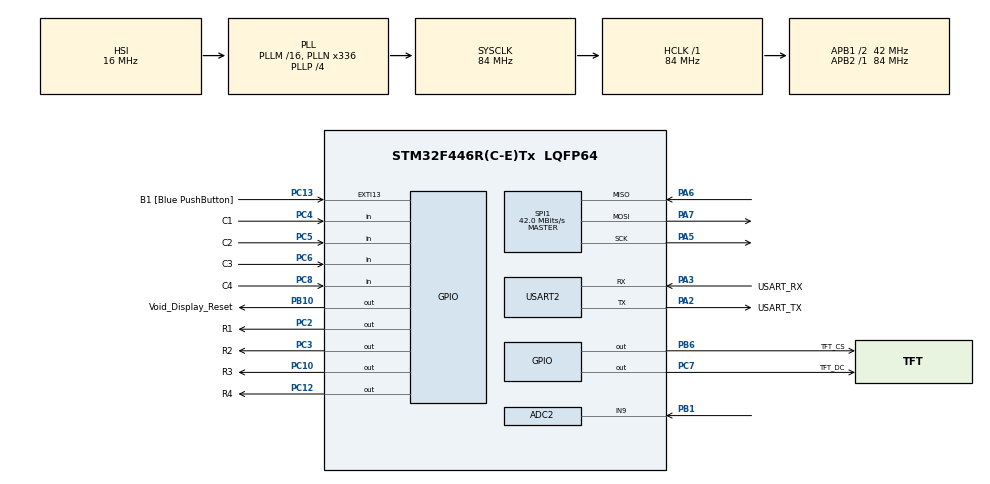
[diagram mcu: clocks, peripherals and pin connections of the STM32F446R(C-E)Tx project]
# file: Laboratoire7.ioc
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ADC1.Channel-0\#ChannelRegularConversion=ADC_CHANNEL_TEMPSENSOR
ADC1.NbrOfConversionFlag=1
ADC1.Rank-0\#ChannelRegularConversion=1
ADC1.SamplingTime-0\#ChannelRegularConversion=ADC_SAMPLETIME_3CYCLES
ADC1.master=1
ADC2.Channel-0\#ChannelRegularConversion=ADC_CHANNEL_9
ADC2.NbrOfConversionFlag=1
ADC2.Rank-0\#ChannelRegularConversion=1
ADC2.SamplingTime-0\#ChannelRegularConversion=ADC_SAMPLETIME_3CYCLES
Dma.Request0=SPI1_TX
Dma.SPI1_TX.0.Direction=DMA_MEMORY_TO_PERIPH
Dma.SPI1_TX.0.FIFOMode=DMA_FIFOMODE_DISABLE
Dma.SPI1_TX.0.Instance=DMA2_Stream3
Dma.SPI1_TX.0.MemDataAlignment=DMA_MDATAALIGN_BYTE
Dma.SPI1_TX.0.MemInc=DMA_MINC_ENABLE
Dma.SPI1_TX.0.Mode=DMA_NORMAL
Dma.SPI1_TX.0.PeriphDataAlignment=DMA_PDATAALIGN_BYTE
Dma.SPI1_TX.0.PeriphInc=DMA_PINC_DISABLE
Dma.SPI1_TX.0.Priority=DMA_PRIORITY_LOW
Mcu.Family=STM32F4
Mcu.Name=STM32F446R(C-E)Tx
Mcu.Package=LQFP64
NVIC.DMA2_Stream3_IRQn=true\:0\:0\:false\:false\:true\:false\:true\:true
NVIC.PriorityGroup=NVIC_PRIORITYGROUP_0
NVIC.SPI1_IRQn=true\:0\:0\:false\:false\:true\:true\:true\:true
NVIC.TIM2_IRQn=true\:0\:0\:false\:false\:true\:true\:true\:true
PA13.GPIO_Label=TMS
PA13.Mode=Serial_Wire
PA13.Signal=SYS_JTMS-SWDIO
PA14.GPIO_Label=TCK
PA14.Mode=Serial_Wire
PA14.Signal=SYS_JTCK-SWCLK
PA2.GPIO_Label=USART_TX
PA2.Mode=Asynchronous
PA2.Signal=USART2_TX
PA3.GPIO_Label=USART_RX
PA3.Mode=Asynchronous
PA3.Signal=USART2_RX
PA5.Mode=Full_Duplex_Master
PA5.Signal=SPI1_SCK
PA6.Mode=Full_Duplex_Master
PA6.Signal=SPI1_MISO
PA7.Mode=Full_Duplex_Master
PA7.Signal=SPI1_MOSI
PB1.Signal=ADCx_IN9
PB10.GPIO_Label=Void_Display_Reset
PB10.Signal=GPIO_Output
PB3.GPIO_Label=SWO
PB3.Signal=SYS_JTDO-SWO
PB6.GPIO_Label=TFT_CS
PB6.Signal=GPIO_Output
PC10.GPIO_Label=R3
PC10.GPIO_ModeDefaultOutputPP=GPIO_MODE_OUTPUT_OD
PC10.GPIO_PuPd=GPIO_NOPULL
PC10.Signal=GPIO_Output
PC12.GPIO_Label=R4
PC12.GPIO_ModeDefaultOutputPP=GPIO_MODE_OUTPUT_OD
PC12.GPIO_PuPd=GPIO_NOPULL
PC12.Signal=GPIO_Output
PC13.GPIO_Label=B1 [Blue PushButton]
PC13.GPIO_ModeDefaultEXTI=GPIO_MODE_IT_FALLING
PC13.Signal=GPXTI13
PC14-OSC32_IN.Mode=LSE-External-Oscillator
PC14-OSC32_IN.Signal=RCC_OSC32_IN
PC15-OSC32_OUT.Mode=LSE-External-Oscillator
PC15-OSC32_OUT.Signal=RCC_OSC32_OUT
PC2.GPIO_Label=R1
PC2.GPIO_ModeDefaultOutputPP=GPIO_MODE_OUTPUT_OD
PC2.GPIO_PuPd=GPIO_NOPULL
PC2.Signal=GPIO_Output
PC3.GPIO_Label=R2
PC3.GPIO_ModeDefaultOutputPP=GPIO_MODE_OUTPUT_OD
PC3.GPIO_PuPd=GPIO_NOPULL
PC3.Signal=GPIO_Output
PC4.GPIO_Label=C1
PC4.GPIO_PuPd=GPIO_PULLUP
PC4.Signal=GPIO_Input
PC5.GPIO_Label=C2
PC5.GPIO_PuPd=GPIO_PULLUP
PC5.Signal=GPIO_Input
PC6.GPIO_Label=C3
PC6.GPIO_PuPd=GPIO_PULLUP
PC6.Signal=GPIO_Input
PC7.GPIO_Label=TFT_DC
PC7.Signal=GPIO_Output
PC8.GPIO_Label=C4
PC8.GPIO_PuPd=GPIO_PULLUP
PC8.Signal=GPIO_Input
PH0-OSC_IN.Mode=HSE-External-Oscillator
PH0-OSC_IN.Signal=RCC_OSC_IN
PH1-OSC_OUT.Mode=HSE-External-Oscillator
PH1-OSC_OUT.Signal=RCC_OSC_OUT
ProjectManager.HeapSize=0x200
ProjectManager.StackSize=0x400
ProjectManager.TargetToolchain=MDK-ARM V5.32
RCC.48MHZClocksFreq_Value=84000000
RCC.AHBFreq_Value=84000000
RCC.APB1CLKDivider=RCC_HCLK_DIV2
RCC.APB1Freq_Value=42000000
RCC.APB1TimFreq_Value=84000000
RCC.APB2Freq_Value=84000000
RCC.APB2TimFreq_Value=84000000
RCC.CortexFreq_Value=84000000
RCC.FLatency-AdvancedSettings=FLASH_LATENCY_2
RCC.HCLKFreq_Value=84000000
RCC.HSE_VALUE=8000000
RCC.HSI_VALUE=16000000
RCC.PLLN=336
RCC.PLLP=RCC_PLLP_DIV4
RCC.SYSCLKFreq_VALUE=84000000
RCC.SYSCLKSource=RCC_SYSCLKSOURCE_PLLCLK
RCC.USBFreq_Value=168000000
RCC.VCOOutputFreq_Value=336000000
SH.ADCx_IN9.0=ADC2_IN9,IN9
SPI1.CalculateBaudRate=42.0 MBits/s
SPI1.Direction=SPI_DIRECTION_2LINES
SPI1.Mode=SPI_MODE_MASTER
SPI1.VirtualType=VM_MASTER
TIM2.Period=999999
TIM2.Prescaler=83
USART2.VirtualMode=VM_ASYNC
VP_ADC1_TempSens_Input.Mode=IN-TempSens
VP_TIM2_VS_ClockSourceINT.Mode=Internal
board=NUCLEO-F446RE

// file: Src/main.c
/*
  laboratoire = 6
  groupe = 2
  date = 2024/octobre/25
  auteurs = Isaac Doré, Arnaud Gagner, Justin Botbol
  équipe = 05
*/

/* USER CODE BEGIN Header */
/**
 ******************************************************************************
 * @file           : main.c
 * @brief          : Main program body
 ******************************************************************************
 * @attention
 *
 * Copyright (c) 2024 STMicroelectronics.
 * All rights reserved.
 *
 * This software is licensed under terms that can be found in the LICENSE file
 * in the root directory of this software component.
 * If no LICENSE file comes with this software, it is provided AS-IS.
 *
 ******************************************************************************
 */
/* USER CODE END Header */
#include "main.h"
#include "adc.h"
#include "dma.h"
#include "gpio.h"
#include "spi.h"
#include "stdio.h"
#include "tim.h"
#include "usart.h"

#define ARM_MATH_CM4
#include "arm_math.h"
#include "time.h"
#include <seed.h>
#include <stdio.h>
#include <stdlib.h>

#include "ili9341.h"
#include "ili9341_gfx.h"

ili9341_t *_screen;
ili9341_text_attr_t text_attr;
char buffer[15] = {0};
float tab_value[256];

// WARNING: positions might be wrong (flip y-axis or wrong screen resolution)
const int screen_width = 320;
const int screen_height = 240;
// pig position
int pig_x;
int pig_y;
// bird data
volatile int vitesse_init = 0;
volatile int lauch = 0;
volatile float angle_init = 0;
volatile float old_x = 0;
volatile float old_y = 0;
volatile float current_x = 12;
volatile float current_y = 220;
volatile float vel_x = 0;
volatile float vel_y = 0;
volatile float gravity = 700000;
// state & flag
volatile int end_flag = 0;
volatile int preparation_state = 0;

void SystemClock_Config(void);

// Timer 2 callback (each 100ms)
void HAL_TIM_PeriodElapsedCallback(TIM_HandleTypeDef *htim) {
  if (lauch == 0 && end_flag != 0) {
    return;
  }

  // TODO: update and draw new position
  float delta_time = 0.00004;
  current_x += vel_x * delta_time;
  current_y += vel_y * delta_time;
  vel_y += gravity * delta_time;

  // checks defeat conditions
  if ((150 <= current_x && current_x <= 170 &&
       current_y >= 120) // hits the wall
      || current_x > 320 - 10 - 1 || current_y > 240 - 10 - 1 ||
      current_y < 0 + 10) {
    end_flag = 2;
    vitesse_init = 0;
  }
  // checks victory condition
  if ((current_x >= pig_x - 20 && current_x <= pig_x + 20) &&
      (current_y >= pig_y - 20 &&
       current_y <= pig_y + 20)) { // TODO: fix to circle hitbox
    end_flag = 1;
    vitesse_init = 0;
  }
}

void HAL_SYSTICK_Callback(void) {
  static int time_while_pressed = 0;

  switch (preparation_state) {
  case 0: // state: repos
    if (HAL_GPIO_ReadPin(GPIOC, C1_Pin) == GPIO_PIN_SET &&
        time_while_pressed == 0) {
      time_while_pressed = 1;
      preparation_state = 1;
    }
    break;
  case 1: // �tat: comptage
    if (HAL_GPIO_ReadPin(GPIOC, C1_Pin) == GPIO_PIN_RESET) {
      preparation_state = 2;
    }
    time_while_pressed++;
    break;
  case 2: // �tat: fin de comptage
    vitesse_init = time_while_pressed;
    break;
  }
}

int main(void) {
  HAL_Init();
  SystemClock_Config();

  MX_GPIO_Init();
  MX_DMA_Init();
  MX_USART2_UART_Init();
  MX_SPI1_Init();
  MX_ADC1_Init();
  MX_ADC2_Init();
  MX_TIM2_Init();

  HAL_ADC_Start(&hadc1);
  HAL_ADC_PollForConversion(&hadc1, 100);
  uint32_t instance_seed = HAL_ADC_GetValue(&hadc1);
  srand(SEED ^ instance_seed);

  _screen = ili9341_new(&hspi1, Void_Display_Reset_GPIO_Port,
                        Void_Display_Reset_Pin, TFT_CS_GPIO_Port, TFT_CS_Pin,
                        TFT_DC_GPIO_Port, TFT_DC_Pin, isoLandscape, NULL, NULL,
                        NULL, NULL, itsNotSupported, itnNormalized);

  ili9341_fill_screen(_screen, ILI9341_BLACK);
  ili9341_text_attr_t text_attr_tmp = {&ili9341_font_11x18, ILI9341_WHITE,
                                       ILI9341_BLACK, 0, 0};

  text_attr = text_attr_tmp;

  HAL_TIM_Base_Start_IT(&htim2);

  while (1) {
    float scale = 90.0 / 4095.0;
    pig_x = rand() % (300 - 180 + 1) +
            180; // random int in range(min,max): % (max - min + 1) + min
    pig_y = 240 -
            (rand() % (140 - 20 + 1) + 20); // knowing the pig has r=20 and the
                                            // zone is x:[160;320] & y:[0;240]

    ili9341_draw_line(_screen, ILI9341_ORANGE, 160, 120 - 1, 160, 0);
    ili9341_fill_circle(_screen, ILI9341_WHITE, (int)current_x, (int)current_y,
                        10);
    ili9341_fill_circle(_screen, ILI9341_PINK, pig_x, pig_y, 20);

    // waits for user to set a speed value before continuing
    while (vitesse_init == 0)
      ;

    sprintf(buffer, "%i", vitesse_init);
    ili9341_draw_string(_screen, text_attr, buffer);
    HAL_ADC_Start(&hadc2);
    HAL_ADC_PollForConversion(&hadc2, 100);
    // calculate the angle of the bird's trajectory depending on user input
    angle_init = HAL_ADC_GetValue(&hadc2) * scale;

    sprintf(buffer, "%.2f", angle_init);
    ili9341_draw_string(_screen, text_attr, buffer);

    HAL_Delay(1000);
    // TODO: all the trajectory
    vel_x = fabs(cos(angle_init * PI / 180.0)) * vitesse_init * 30;
    vel_y = -fabs(sin(angle_init * PI / 180.0)) * vitesse_init * 30;

    current_y = 220;
    lauch = 1;
    old_x = current_x;
    old_y = current_y;
    while (end_flag == 0) {
      ili9341_fill_circle(_screen, ILI9341_BLACK, (int)old_x, (int)old_y, 10);
      old_x = current_x;
      old_y = current_y;
      sprintf(buffer, "%.2f;%.2f", vel_x, vel_y);
      ili9341_draw_string(_screen, text_attr, buffer);
      // ili9341_fill_screen(_screen, ILI9341_BLACK);
      // ili9341_fill_circle(_screen, ILI9341_PINK, pig_x, pig_y, 20);
      // ili9341_draw_line(_screen, ILI9341_ORANGE, 160, 120 - 1, 160, 0);
      ili9341_fill_circle(_screen, ILI9341_WHITE, (int)current_x,
                          (int)current_y, 10);
    }

    ili9341_fill_screen(_screen, ILI9341_BLACK);
    // char buffer[15] = {0};
    if (end_flag == 1) {
      sprintf(buffer, "Victoire :)");
      ili9341_draw_string(_screen, text_attr, buffer);
    } else {
      sprintf(buffer, "Skill issue.");
      ili9341_draw_string(_screen, text_attr, buffer);
    }

    while (1)
      ;
    // Prelab stuff
    // Experience 1
    //		while(flag_timer_2 == 0);
    //		flag_timer_2 = 0;
    //		ili9341_fill_circle(_screen, ILI9341_WHITE, 160, 120, 20);
    //
    //		while(flag_timer_2 == 0);
    //		flag_timer_2 = 0;
    //		ili9341_fill_circle(_screen, ILI9341_BLACK, 160, 120, 20);

    // Experience 2
    //		int x;
    //		float scale = 120.0/4095.0;
    //		for (int x=0;x<256;x++) {
    //			while(flag_timer_2 == 0);
    //			flag_timer_2 = 0;
    //
    //			HAL_ADC_Start(&hadc2);
    //			HAL_ADC_PollForConversion(&hadc2,100);
    //			float value = tab_value[x] =
    // HAL_ADC_GetValue(&hadc2)*scale;
    //
    //			char buffer[15] = {0};
    //			sprintf(buffer, "Value : %-6.2f",value);
    //
    //			ili9341_draw_string(_screen, text_attr, buffer);
    //			ili9341_draw_pixel(_screen, ILI9341_BLUE, x,(int)
    //(120-value));
    //		}

    // Experience 3
    //		while(flag_systick_timer == 0);
    //		flag_systick_timer = 0;
    //
    //		char buffer[15] = {0};
    //		sprintf(buffer, "State : %3i", current_state);
    //		ili9341_draw_string(_screen, text_attr,buffer);
  }
}

void SystemClock_Config(void) {
  RCC_OscInitTypeDef RCC_OscInitStruct = {0};
  RCC_ClkInitTypeDef RCC_ClkInitStruct = {0};

  /** Configure the main internal regulator output voltage
   */
  __HAL_RCC_PWR_CLK_ENABLE();
  __HAL_PWR_VOLTAGESCALING_CONFIG(PWR_REGULATOR_VOLTAGE_SCALE3);

  /** Initializes the RCC Oscillators according to the specified parameters
   * in the RCC_OscInitTypeDef structure.
   */
  RCC_OscInitStruct.OscillatorType = RCC_OSCILLATORTYPE_HSI;
  RCC_OscInitStruct.HSIState = RCC_HSI_ON;
  RCC_OscInitStruct.HSICalibrationValue = RCC_HSICALIBRATION_DEFAULT;
  RCC_OscInitStruct.PLL.PLLState = RCC_PLL_ON;
  RCC_OscInitStruct.PLL.PLLSource = RCC_PLLSOURCE_HSI;
  RCC_OscInitStruct.PLL.PLLM = 16;
  RCC_OscInitStruct.PLL.PLLN = 336;
  RCC_OscInitStruct.PLL.PLLP = RCC_PLLP_DIV4;
  RCC_OscInitStruct.PLL.PLLQ = 2;
  RCC_OscInitStruct.PLL.PLLR = 2;
  if (HAL_RCC_OscConfig(&RCC_OscInitStruct) != HAL_OK) {
    Error_Handler();
  }

  /** Initializes the CPU, AHB and APB buses clocks
   */
  RCC_ClkInitStruct.ClockType = RCC_CLOCKTYPE_HCLK | RCC_CLOCKTYPE_SYSCLK |
                                RCC_CLOCKTYPE_PCLK1 | RCC_CLOCKTYPE_PCLK2;
  RCC_ClkInitStruct.SYSCLKSource = RCC_SYSCLKSOURCE_PLLCLK;
  RCC_ClkInitStruct.AHBCLKDivider = RCC_SYSCLK_DIV1;
  RCC_ClkInitStruct.APB1CLKDivider = RCC_HCLK_DIV2;
  RCC_ClkInitStruct.APB2CLKDivider = RCC_HCLK_DIV1;

  if (HAL_RCC_ClockConfig(&RCC_ClkInitStruct, FLASH_LATENCY_2) != HAL_OK) {
    Error_Handler();
  }
}

void Error_Handler(void) {
  __disable_irq();
  while (1) {
  }
}

#ifdef USE_FULL_ASSERT
/**
 * @brief  Reports the name of the source file and the source line number
 *         where the assert_param error has occurred.
 * @param  file: pointer to the source file name
 * @param  line: assert_param error line source number
 * @retval None
 */
void assert_failed(uint8_t *file, uint32_t line) {
  /* USER CODE BEGIN 6 */
  /* User can add his own implementation to report the file name and line
     number,
     ex: printf("Wrong parameters value: file %s on line %d\r\n", file, line) */
  /* USER CODE END 6 */
}
#endif /* USE_FULL_ASSERT */
